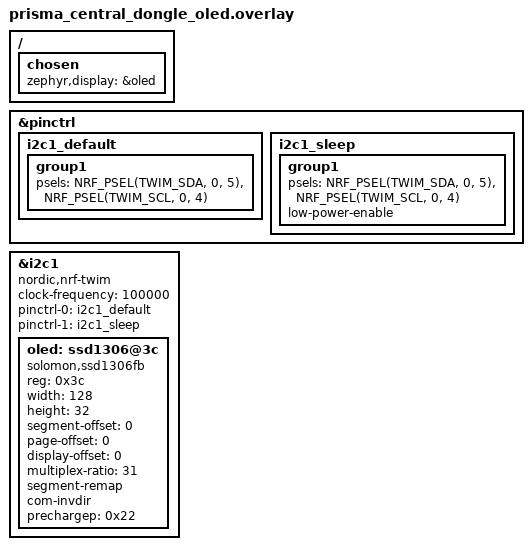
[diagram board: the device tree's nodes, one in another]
/* XIAO carrier CK = D4/P0.04, IO = D5/P0.05 (not default XIAO I2C order). */
#include "prisma_dongle.dtsi"

/ { chosen { zephyr,display = &oled; }; };

&pinctrl {
    i2c1_default: i2c1_default {
        group1 { psels = <NRF_PSEL(TWIM_SDA, 0, 5)>, <NRF_PSEL(TWIM_SCL, 0, 4)>; };
    };
    i2c1_sleep: i2c1_sleep {
        group1 {
            psels = <NRF_PSEL(TWIM_SDA, 0, 5)>, <NRF_PSEL(TWIM_SCL, 0, 4)>;
            low-power-enable;
        };
    };
};
&i2c1 {
    status = "okay";
    compatible = "nordic,nrf-twim";
    clock-frequency = <100000>;
    pinctrl-0 = <&i2c1_default>;
    pinctrl-1 = <&i2c1_sleep>;
    pinctrl-names = "default", "sleep";
    oled: ssd1306@3c {
        compatible = "solomon,ssd1306fb";
        reg = <0x3c>;
        width = <128>;
        height = <32>;
        segment-offset = <0>;
        page-offset = <0>;
        display-offset = <0>;
        multiplex-ratio = <31>;
        segment-remap;
        com-invdir;
        prechargep = <0x22>;
    };
};
